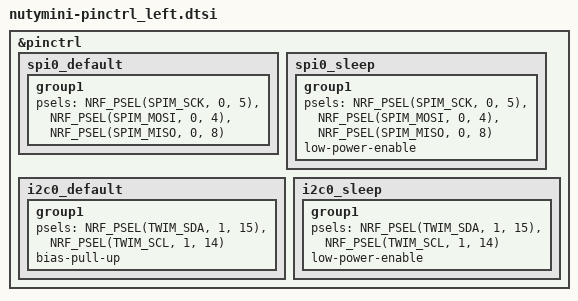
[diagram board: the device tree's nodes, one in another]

#include <dt-bindings/zmk/matrix_transform.h>
//#include <dt-bindings/pinctrl/nrf-pinctrl.h>
#include "nutymini-layouts.dtsi"

&pinctrl {
	spi0_default: spi0_default {
		group1 {
			psels = <NRF_PSEL(SPIM_SCK, 0, 5)>,
				<NRF_PSEL(SPIM_MOSI, 0, 4)>,
				<NRF_PSEL(SPIM_MISO, 0, 8)>;
		};
	};
	spi0_sleep: spi0_sleep {
		group1 {
			psels = <NRF_PSEL(SPIM_SCK, 0, 5)>,
				<NRF_PSEL(SPIM_MOSI, 0, 4)>,
				<NRF_PSEL(SPIM_MISO, 0, 8)>;
			low-power-enable;
		};
	};	
    i2c0_default: i2c0_default {
        group1 {
            psels = <NRF_PSEL(TWIM_SDA, 1, 15)>,
                <NRF_PSEL(TWIM_SCL, 1, 14)>;
            bias-pull-up;
        };
    };
    i2c0_sleep: i2c0_sleep {
        group1 {
            psels = <NRF_PSEL(TWIM_SDA, 1, 15)>,
                <NRF_PSEL(TWIM_SCL, 1, 14)>;
            low-power-enable;
        };
    };
};



//&xiao_i2c {
//    status = "okay";
//
//    oled_128x32: ssd1306@3c {
//        compatible = "solomon,ssd1306fb";
//        reg = <0x3c>;
//        width = <128>;
//        height = <32>;
//        segment-offset = <0>;
//        page-offset = <0>;
//        display-offset = <0>;
//        multiplex-ratio = <31>;
//        segment-remap;
//        com-invdir;
//        com-sequential;
//        inversion-on;
//        prechargep = <0x22>;
//    };
//};


